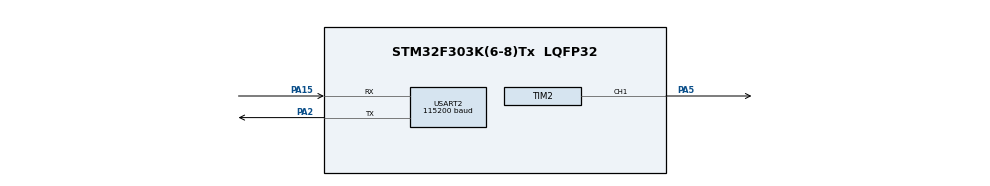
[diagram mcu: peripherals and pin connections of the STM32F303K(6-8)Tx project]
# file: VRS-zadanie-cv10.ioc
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Dma.Request0=USART2_RX
Dma.Request1=USART2_TX
Dma.USART2_RX.0.Direction=DMA_PERIPH_TO_MEMORY
Dma.USART2_RX.0.Instance=DMA1_Channel6
Dma.USART2_RX.0.MemDataAlignment=DMA_MDATAALIGN_BYTE
Dma.USART2_RX.0.MemInc=DMA_MINC_ENABLE
Dma.USART2_RX.0.Mode=DMA_NORMAL
Dma.USART2_RX.0.PeriphDataAlignment=DMA_PDATAALIGN_BYTE
Dma.USART2_RX.0.PeriphInc=DMA_PINC_DISABLE
Dma.USART2_RX.0.Priority=DMA_PRIORITY_MEDIUM
Dma.USART2_TX.1.Direction=DMA_MEMORY_TO_PERIPH
Dma.USART2_TX.1.Instance=DMA1_Channel7
Dma.USART2_TX.1.MemDataAlignment=DMA_MDATAALIGN_BYTE
Dma.USART2_TX.1.MemInc=DMA_MINC_ENABLE
Dma.USART2_TX.1.Mode=DMA_NORMAL
Dma.USART2_TX.1.PeriphDataAlignment=DMA_PDATAALIGN_BYTE
Dma.USART2_TX.1.PeriphInc=DMA_PINC_DISABLE
Dma.USART2_TX.1.Priority=DMA_PRIORITY_MEDIUM
Mcu.Family=STM32F3
Mcu.Name=STM32F303K(6-8)Tx
Mcu.Package=LQFP32
NVIC.DMA1_Channel6_IRQn=true\:0\:0\:false\:false\:true\:false\:true
NVIC.DMA1_Channel7_IRQn=true\:0\:0\:false\:false\:true\:false\:true
NVIC.PriorityGroup=NVIC_PRIORITYGROUP_4
NVIC.TIM2_IRQn=true\:0\:0\:false\:false\:true\:true\:true
NVIC.USART2_IRQn=true\:0\:0\:false\:false\:true\:true\:true
PA15.Mode=Asynchronous
PA15.Signal=USART2_RX
PA2.Mode=Asynchronous
PA2.Signal=USART2_TX
PA5.Signal=S_TIM2_CH1_ETR
ProjectManager.HeapSize=0x200
ProjectManager.StackSize=0x400
ProjectManager.TargetToolchain=STM32CubeIDE
RCC.AHBFreq_Value=8000000
RCC.APB1Freq_Value=8000000
RCC.APB2Freq_Value=8000000
RCC.CortexFreq_Value=8000000
RCC.HSE_VALUE=8000000
RCC.HSI_VALUE=8000000
RCC.SYSCLKFreq_VALUE=8000000
SH.S_TIM2_CH1_ETR.0=TIM2_CH1,PWM Generation1 CH1
TIM2.AutoReloadPreload=TIM_AUTORELOAD_PRELOAD_ENABLE
TIM2.Channel-Output\ Compare2\ No\ Output=TIM_CHANNEL_2
TIM2.Channel-PWM\ Generation1\ CH1=TIM_CHANNEL_1
TIM2.OC2Preload=DISABLE
TIM2.OCMode_2=TIM_OCMODE_ACTIVE
TIM2.Period=99
TIM2.Prescaler=799
TIM2.Pulse-PWM\ Generation1\ CH1=0
USART2.BaudRate=115200
USART2.VirtualMode-Asynchronous=VM_ASYNC
VP_TIM2_VS_ClockSourceINT.Mode=Internal
VP_TIM2_VS_no_output2.Mode=Output Compare2 No Output
board=custom

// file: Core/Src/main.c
/* USER CODE BEGIN Header */
/**
  ******************************************************************************
  * @file           : main.c
  * @brief          : Main program body
  ******************************************************************************
  * @attention
  *
  * <h2><center>&copy; Copyright (c) 2021 STMicroelectronics.
  * All rights reserved.</center></h2>
  *
  * This software component is licensed by ST under BSD 3-Clause license,
  * the "License"; You may not use this file except in compliance with the
  * License. You may obtain a copy of the License at:
  *                        opensource.org/licenses/BSD-3-Clause
  *
  ******************************************************************************
  */
/* USER CODE END Header */
#include "main.h"
#include "dma.h"
#include "tim.h"
#include "usart.h"
#include "gpio.h"

/* USER CODE BEGIN Includes */
#include "string.h"
#include "stdio.h"
#include "stdlib.h"
/* USER CODE END Includes */

void SystemClock_Config(void);

/* USER CODE BEGIN 0 */
void proccesDmaData(uint8_t sign);
/* USER CODE END 0 */

int main(void)
{

  /* MCU Configuration--------------------------------------------------------*/

  /* Reset of all peripherals, Initializes the Flash interface and the Systick. */

  LL_APB2_GRP1_EnableClock(LL_APB2_GRP1_PERIPH_SYSCFG);
  LL_APB1_GRP1_EnableClock(LL_APB1_GRP1_PERIPH_PWR);

  NVIC_SetPriorityGrouping(NVIC_PRIORITYGROUP_4);

  /* System interrupt init*/
  /* SysTick_IRQn interrupt configuration */
  NVIC_SetPriority(SysTick_IRQn, NVIC_EncodePriority(NVIC_GetPriorityGrouping(),15, 0));

  /* Configure the system clock */
  SystemClock_Config();

  /* Initialize all configured peripherals */
  MX_GPIO_Init();
  MX_DMA_Init();
  MX_USART2_UART_Init();
  MX_TIM2_Init();
  /* USER CODE BEGIN 2 */
  USART2_RegisterCallback(proccesDmaData); //DMA callback init

   dutyCycle = 0; //default duty cycle
   mode = 0;
   countUpDown = 1;
   dutyCycleManual = 0;

   /*While loop definitions*/
  char data_to_send[100];
  char actual_data_buffer[256];
  strcpy(actual_data_buffer,"");

  /* USER CODE END 2 */

  /* Infinite loop */
  /* USER CODE BEGIN WHILE */
  while (1)
  {
	  //Sending info about buffer capacity status - debug
	  	  /*uint16_t buffer_state = getBufferState();
	  	  float buffer_percentage = (float) (buffer_state) / (float) (DMA_USART2_BUFFER_SIZE)*100;
	  	  sprintf(data_to_send, "Buffer capacity: %d bytes, occupied memory: %d bytes, load [in %%]:%.2f%%\r\n", DMA_USART2_BUFFER_SIZE, buffer_state, buffer_percentage);

	  	  USART2_PutBuffer((uint8_t *) data_to_send, strlen(data_to_send));
	  	  LL_mDelay(10000);*/
    /* USER CODE END WHILE */

  }
}

void SystemClock_Config(void)
{
  LL_FLASH_SetLatency(LL_FLASH_LATENCY_0);
  while(LL_FLASH_GetLatency()!= LL_FLASH_LATENCY_0)
  {
  }
  LL_RCC_HSI_Enable();

   /* Wait till HSI is ready */
  while(LL_RCC_HSI_IsReady() != 1)
  {

  }
  LL_RCC_HSI_SetCalibTrimming(16);
  LL_RCC_SetAHBPrescaler(LL_RCC_SYSCLK_DIV_1);
  LL_RCC_SetAPB1Prescaler(LL_RCC_APB1_DIV_1);
  LL_RCC_SetAPB2Prescaler(LL_RCC_APB2_DIV_1);
  LL_RCC_SetSysClkSource(LL_RCC_SYS_CLKSOURCE_HSI);

   /* Wait till System clock is ready */
  while(LL_RCC_GetSysClkSource() != LL_RCC_SYS_CLKSOURCE_STATUS_HSI)
  {

  }
  LL_Init1msTick(8000000);
  LL_SetSystemCoreClock(8000000);
}

/* USER CODE BEGIN 4 */
void proccesDmaData(uint8_t sign)
{
	if(sign == '\r') return; //odstranenie znaku, ktory sa vygeneruje po stlaceni enteru v puTTY

	static char readed_text[20] = "";
	static int start = 0;
	char new_letter[2] = {sign,'\0'};
	static char read_duty_cycle_text[10] = "";

    if(sign == '$' && start == 0){
        start = 1;
    }
    else if( sign == '$' && start == 1){
    	start = 0;
        if(strcmp("$manual",readed_text) == 0){
            mode = 1;
            strcpy(readed_text,"");
        }
        if(strcmp("$auto",readed_text) == 0){
            mode = 0;
            strcpy(readed_text,"");

        }
        if(mode == 1){
	    if (strlen(readed_text) != 6){//posledny $ sa nepridava do readed_text
                strcpy(readed_text,"");
	    }
            if(strncmp("$PWM",readed_text,4)==0){
		if((readed_text[4] >= '0' && readed_text[4] <= '9') && (readed_text[5] >= '0' && readed_text[5] <= '9')) {
                    for(int j = 0; j<2; j++){
                        read_duty_cycle_text[j]=readed_text[j+4];
                    }
                    dutyCycleManual = atoi(read_duty_cycle_text);
                    strcpy(readed_text,"");
		} else strcpy(readed_text,"");
            }
        }
    }
    if(start == 1){
         strcat(readed_text, new_letter);
    } else strcpy(readed_text,"");

}
/* USER CODE END 4 */

void Error_Handler(void)
{
  __disable_irq();
  while (1)
  {
  }
}

/************************ (C) COPYRIGHT STMicroelectronics *****END OF FILE****/
